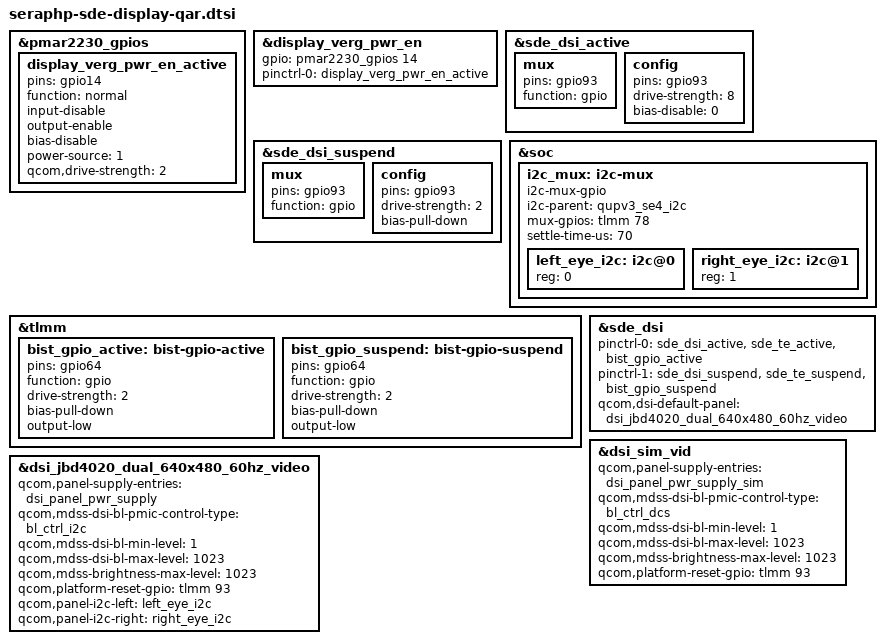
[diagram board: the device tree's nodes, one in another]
// SPDX-License-Identifier: BSD-3-Clause
/*
 * Copyright (c) Qualcomm Technologies, Inc. and/or its subsidiaries.
 */

#include "seraph-sde-display.dtsi"
#include <dt-bindings/gpio/gpio.h>

&pmar2230_gpios {
	display_verg_pwr_en_active: display_verg_pwr_en_active {
		pins = "gpio14";
		function = "normal";
		input-disable;
		output-enable;
		bias-disable;
		power-source = <1>;
		qcom,drive-strength = <2>;
	};
};

&display_verg_pwr_en {
	gpio = <&pmar2230_gpios 14 0>;
	pinctrl-names = "default";
	pinctrl-0 = <&display_verg_pwr_en_active>;
};

&sde_dsi_active {
	mux {
		pins = "gpio93";
		function = "gpio";
	};

	config {
		pins = "gpio93";
		drive-strength = <8>;   /* 8 mA */
		bias-disable = <0>;   /* no pull */
	};
};

&sde_dsi_suspend {
	mux {
		pins = "gpio93";
		function = "gpio";
	};

	config {
		pins = "gpio93";
		drive-strength = <2>;   /* 2 mA */
		bias-pull-down;         /* PULL DOWN */
	};
};

&soc {
	i2c_mux: i2c-mux {
		compatible = "i2c-mux-gpio";
		i2c-parent = <&qupv3_se4_i2c>;
		mux-gpios = <&tlmm 78 GPIO_ACTIVE_HIGH>;
		settle-time-us = <70>;

		#address-cells = <1>;
		#size-cells = <0>;

		left_eye_i2c: i2c@0 {
			reg = <0>;
			#address-cells = <1>;
			#size-cells = <0>;
		};

		right_eye_i2c: i2c@1 {
			reg = <1>;
			#address-cells = <1>;
			#size-cells = <0>;
		};
	};
};

&tlmm {
	bist_gpio_active: bist-gpio-active {
		pins = "gpio64";
		function = "gpio";
		drive-strength = <2>;
		bias-pull-down;
		output-low;
	};

	bist_gpio_suspend: bist-gpio-suspend {
		pins = "gpio64";
		function = "gpio";
		drive-strength = <2>;
		bias-pull-down;
		output-low;
	};
};

&sde_dsi {
	pinctrl-0 = <&sde_dsi_active &sde_te_active &bist_gpio_active>;
	pinctrl-1 = <&sde_dsi_suspend &sde_te_suspend &bist_gpio_suspend>;
};

&dsi_jbd4020_dual_640x480_60hz_video {
	qcom,panel-supply-entries = <&dsi_panel_pwr_supply>;
	qcom,mdss-dsi-bl-pmic-control-type = "bl_ctrl_i2c";
	qcom,mdss-dsi-bl-min-level = <1>;
	qcom,mdss-dsi-bl-max-level = <1023>;
	qcom,mdss-brightness-max-level = <1023>;
	qcom,platform-reset-gpio = <&tlmm 93 0>;
	qcom,panel-i2c-left  = <&left_eye_i2c>;
	qcom,panel-i2c-right  = <&right_eye_i2c>;
};

&dsi_sim_vid {
	qcom,panel-supply-entries = <&dsi_panel_pwr_supply_sim>;
	qcom,mdss-dsi-bl-pmic-control-type = "bl_ctrl_dcs";
	qcom,mdss-dsi-bl-min-level = <1>;
	qcom,mdss-dsi-bl-max-level = <1023>;
	qcom,mdss-brightness-max-level = <1023>;
	qcom,platform-reset-gpio = <&tlmm 93 0>;
};

&sde_dsi {
	qcom,dsi-default-panel = <&dsi_jbd4020_dual_640x480_60hz_video>;
};
